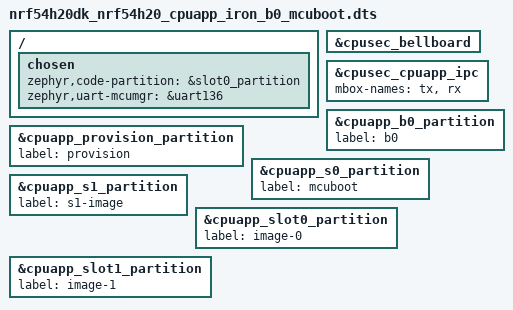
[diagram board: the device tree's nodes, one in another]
/*
 * Copyright (c) 2025 Nordic Semiconductor ASA
 *
 * SPDX-License-Identifier: LicenseRef-Nordic-5-Clause
 */

#include "../../../../zephyr/boards/nordic/nrf54h20dk/nrf54h20dk_nrf54h20_cpuapp.dts"
#include "../../../../zephyr/boards/nordic/nrf54h20dk/nrf54h20dk_nrf54h20-ipc_conf_iron.dtsi"
#include "nrf54h20dk_nrf54h20-memory_map_iron_b0_mcuboot.dtsi"

/delete-node/ &cpusec_cpurad_ipc;

/ {
	chosen {
		zephyr,code-partition = &slot0_partition;
		zephyr,uart-mcumgr = &uart136;
	};
};

&cpusec_bellboard {
	status = "okay";
};

&cpusec_cpuapp_ipc {
	mbox-names = "tx", "rx";
	status = "okay";
};

b0_partition: &cpuapp_b0_partition {
	label = "b0";
};

provision_partition: &cpuapp_provision_partition {
	label = "provision";
};

s0_partition: &cpuapp_s0_partition {
};

s1_partition: &cpuapp_s1_partition {
	label = "s1-image";
};

slot0_partition: &cpuapp_slot0_partition {
	label = "image-0";
};

slot1_partition: &cpuapp_slot1_partition {
	label = "image-1";
};

boot_partition: &s0_partition {
	label = "mcuboot";
};
